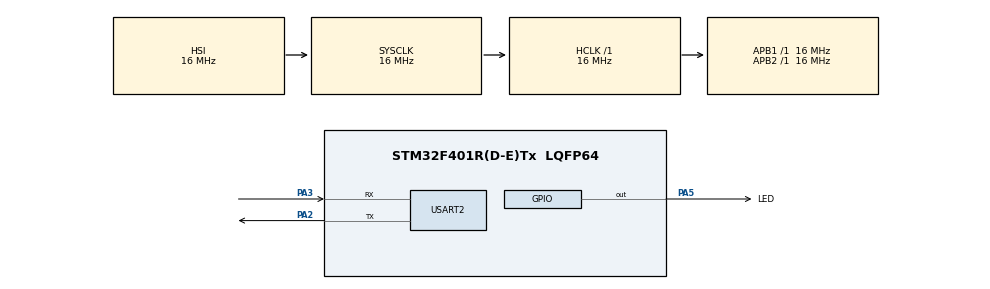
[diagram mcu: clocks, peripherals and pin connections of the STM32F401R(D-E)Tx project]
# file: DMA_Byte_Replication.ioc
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Dma.MEMTOMEM.0.Direction=DMA_MEMORY_TO_MEMORY
Dma.MEMTOMEM.0.FIFOMode=DMA_FIFOMODE_ENABLE
Dma.MEMTOMEM.0.FIFOThreshold=DMA_FIFO_THRESHOLD_FULL
Dma.MEMTOMEM.0.Instance=DMA2_Stream0
Dma.MEMTOMEM.0.MemBurst=DMA_MBURST_SINGLE
Dma.MEMTOMEM.0.MemDataAlignment=DMA_MDATAALIGN_BYTE
Dma.MEMTOMEM.0.MemInc=DMA_MINC_ENABLE
Dma.MEMTOMEM.0.Mode=DMA_NORMAL
Dma.MEMTOMEM.0.PeriphBurst=DMA_PBURST_SINGLE
Dma.MEMTOMEM.0.PeriphDataAlignment=DMA_PDATAALIGN_BYTE
Dma.MEMTOMEM.0.PeriphInc=DMA_PINC_ENABLE
Dma.MEMTOMEM.0.Priority=DMA_PRIORITY_LOW
Dma.Request0=MEMTOMEM
Mcu.Family=STM32F4
Mcu.Name=STM32F401R(D-E)Tx
Mcu.Package=LQFP64
NVIC.PriorityGroup=NVIC_PRIORITYGROUP_4
PA2.Mode=Asynchronous
PA2.Signal=USART2_TX
PA3.Mode=Asynchronous
PA3.Signal=USART2_RX
PA5.GPIO_Label=LED
PA5.Signal=GPIO_Output
ProjectManager.HeapSize=0x200
ProjectManager.StackSize=0x400
ProjectManager.TargetToolchain=STM32CubeIDE
RCC.AHBFreq_Value=16000000
RCC.APB1Freq_Value=16000000
RCC.APB2Freq_Value=16000000
RCC.CortexFreq_Value=16000000
RCC.HSE_VALUE=25000000
RCC.HSI_VALUE=16000000
RCC.LSE_VALUE=32768
RCC.SYSCLKFreq_VALUE=16000000
RCC.VCOOutputFreq_Value=192000000
USART2.VirtualMode=VM_ASYNC
board=custom

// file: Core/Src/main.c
/* USER CODE BEGIN Header */
/**
  ******************************************************************************
  * @file           : main.c
  * @brief          : Main program body
  ******************************************************************************
  * @attention
  *
  * <h2><center>&copy; Copyright (c) 2020 STMicroelectronics.
  * All rights reserved.</center></h2>
  *
  * This software component is licensed by ST under BSD 3-Clause license,
  * the "License"; You may not use this file except in compliance with the
  * License. You may obtain a copy of the License at:
  *                        opensource.org/licenses/BSD-3-Clause
  *
  ******************************************************************************
  */
/* USER CODE END Header */
#include "main.h"

/* USER CODE BEGIN Includes */
#include "string.h"
#include "stdio.h"
#include "stdint.h"
#include "stdarg.h"
/* USER CODE END Includes */

/* USER CODE BEGIN PD */
#define LED_BANK GPIOA
#define LED_PIN GPIO_PIN_5
#define LOW 0
#define HIGH 1
/* USER CODE END PD */

UART_HandleTypeDef huart2;

DMA_HandleTypeDef myDMA;
/* USER CODE BEGIN PV */
const int DATA_SIZE = 4096;	//can not use #define to declare array size?
/* USER CODE END PV */

void SystemClock_Config(void);
static void MX_GPIO_Init(void);
static void MX_DMA_Init(void);
static void MX_USART2_UART_Init(void);
/* USER CODE BEGIN PFP */
void printmsg(char *format,...);
/* USER CODE END PFP */

int main(void)
{
  /* USER CODE BEGIN 1 */
	HAL_GPIO_WritePin(LED_BANK, LED_PIN, LOW);
	uint8_t srcData[DATA_SIZE];
	uint8_t dstData[DATA_SIZE];

	for(int i = 0; i < DATA_SIZE; i++)
	{
		srcData[i] = i%DATA_SIZE;
		dstData[i] = 0;
	}
  /* USER CODE END 1 */

  /* MCU Configuration--------------------------------------------------------*/

  /* Reset of all peripherals, Initializes the Flash interface and the Systick. */
  HAL_Init();

  /* Configure the system clock */
  SystemClock_Config();

  /* Initialize all configured peripherals */
  MX_GPIO_Init();
  MX_DMA_Init();
  MX_USART2_UART_Init();
  /* USER CODE BEGIN 2 */
  HAL_DMA_Start(&myDMA, (uint32_t)srcData, (uint32_t)dstData, sizeof(srcData));
  /* USER CODE END 2 */

  /* Infinite loop */
  /* USER CODE BEGIN WHILE */
  while (1)
  {
	printmsg("waiting for ISR...\n\n");
	HAL_StatusTypeDef DMA_Status = HAL_DMA_PollForTransfer(&myDMA, HAL_DMA_FULL_TRANSFER, HAL_MAX_DELAY);
	if(DMA_Status == HAL_OK)
	{
		printmsg("| ");
		for(int i = 0; i < DATA_SIZE; i++){
			if(i%16 == 0 && i){
				printmsg("\n| ");
			}
			printmsg("0x%02X | ", dstData[i]);
		}
		HAL_GPIO_WritePin(LED_BANK, LED_PIN, HIGH);
		while(1);
		printmsg("\n\n");
	}
    /* USER CODE END WHILE */

  }
}

void SystemClock_Config(void)
{
  RCC_OscInitTypeDef RCC_OscInitStruct = {0};
  RCC_ClkInitTypeDef RCC_ClkInitStruct = {0};

  /** Configure the main internal regulator output voltage
  */
  __HAL_RCC_PWR_CLK_ENABLE();
  __HAL_PWR_VOLTAGESCALING_CONFIG(PWR_REGULATOR_VOLTAGE_SCALE2);
  /** Initializes the RCC Oscillators according to the specified parameters
  * in the RCC_OscInitTypeDef structure.
  */
  RCC_OscInitStruct.OscillatorType = RCC_OSCILLATORTYPE_HSI;
  RCC_OscInitStruct.HSIState = RCC_HSI_ON;
  RCC_OscInitStruct.HSICalibrationValue = RCC_HSICALIBRATION_DEFAULT;
  RCC_OscInitStruct.PLL.PLLState = RCC_PLL_NONE;
  if (HAL_RCC_OscConfig(&RCC_OscInitStruct) != HAL_OK)
  {
    Error_Handler();
  }
  /** Initializes the CPU, AHB and APB buses clocks
  */
  RCC_ClkInitStruct.ClockType = RCC_CLOCKTYPE_HCLK|RCC_CLOCKTYPE_SYSCLK
                              |RCC_CLOCKTYPE_PCLK1|RCC_CLOCKTYPE_PCLK2;
  RCC_ClkInitStruct.SYSCLKSource = RCC_SYSCLKSOURCE_HSI;
  RCC_ClkInitStruct.AHBCLKDivider = RCC_SYSCLK_DIV1;
  RCC_ClkInitStruct.APB1CLKDivider = RCC_HCLK_DIV1;
  RCC_ClkInitStruct.APB2CLKDivider = RCC_HCLK_DIV1;

  if (HAL_RCC_ClockConfig(&RCC_ClkInitStruct, FLASH_LATENCY_0) != HAL_OK)
  {
    Error_Handler();
  }
}

static void MX_USART2_UART_Init(void)
{

  huart2.Instance = USART2;
  huart2.Init.BaudRate = 115200;
  huart2.Init.WordLength = UART_WORDLENGTH_8B;
  huart2.Init.StopBits = UART_STOPBITS_1;
  huart2.Init.Parity = UART_PARITY_NONE;
  huart2.Init.Mode = UART_MODE_TX_RX;
  huart2.Init.HwFlowCtl = UART_HWCONTROL_NONE;
  huart2.Init.OverSampling = UART_OVERSAMPLING_16;
  if (HAL_UART_Init(&huart2) != HAL_OK)
  {
    Error_Handler();
  }

}

static void MX_DMA_Init(void)
{

  /* DMA controller clock enable */
  __HAL_RCC_DMA2_CLK_ENABLE();

  /* Configure DMA request hdma_memtomem_dma2_stream0 on DMA2_Stream0 */
  myDMA.Instance = DMA2_Stream0;
  myDMA.Init.Channel = DMA_CHANNEL_0;
  myDMA.Init.Direction = DMA_MEMORY_TO_MEMORY;
  myDMA.Init.PeriphInc = DMA_PINC_ENABLE;
  myDMA.Init.MemInc = DMA_MINC_ENABLE;
  myDMA.Init.PeriphDataAlignment = DMA_PDATAALIGN_BYTE;
  myDMA.Init.MemDataAlignment = DMA_MDATAALIGN_BYTE;
  myDMA.Init.Mode = DMA_NORMAL;
  myDMA.Init.Priority = DMA_PRIORITY_LOW;
  myDMA.Init.FIFOMode = DMA_FIFOMODE_ENABLE;
  myDMA.Init.FIFOThreshold = DMA_FIFO_THRESHOLD_FULL;
  myDMA.Init.MemBurst = DMA_MBURST_SINGLE;
  myDMA.Init.PeriphBurst = DMA_PBURST_SINGLE;
  if (HAL_DMA_Init(&myDMA) != HAL_OK)
  {
    Error_Handler( );
  }

}

static void MX_GPIO_Init(void)
{
  GPIO_InitTypeDef GPIO_InitStruct = {0};

  /* GPIO Ports Clock Enable */
  __HAL_RCC_GPIOA_CLK_ENABLE();

  /*Configure GPIO pin Output Level */
  HAL_GPIO_WritePin(LED_GPIO_Port, LED_Pin, GPIO_PIN_RESET);

  /*Configure GPIO pin : LED_Pin */
  GPIO_InitStruct.Pin = LED_Pin;
  GPIO_InitStruct.Mode = GPIO_MODE_OUTPUT_PP;
  GPIO_InitStruct.Pull = GPIO_NOPULL;
  GPIO_InitStruct.Speed = GPIO_SPEED_FREQ_LOW;
  HAL_GPIO_Init(LED_GPIO_Port, &GPIO_InitStruct);

}

/* USER CODE BEGIN 4 */
void printmsg(char *format,...) {
    char str[80];

    /*Extract the the argument list using VA apis */
    va_list args;
    va_start(args, format);
    vsprintf(str, format,args);
    HAL_UART_Transmit(&huart2,(uint8_t *)str, strlen(str),HAL_MAX_DELAY);
    va_end(args);
}
/* USER CODE END 4 */

void Error_Handler(void)
{
}

/************************ (C) COPYRIGHT STMicroelectronics *****END OF FILE****/
